# RL7005_IP_SVD register map
Vendor: Realtek
Registers are 32-bit, read-write, reset 0x0 unless marked. A register's access mark holds for its fields unless they carry their own. Offsets are from the block's base; [hi:lo] are bit positions; {n}, {i} and the like mark numbered series.

## TIMER0_REG
Base 0x40819000
Same registers: TIMER1_REG 0x40819200, TIMER2_REG 0x40819400, TIMER3_REG 0x40819600, TIMER4_REG 0x41000000, TIMER5_REG 0x41000200, TIMER6_REG 0x41000400, TIMER7_REG 0x41000600, TIMER8_REG 0x41000800, UPS_REG 0x41000A00
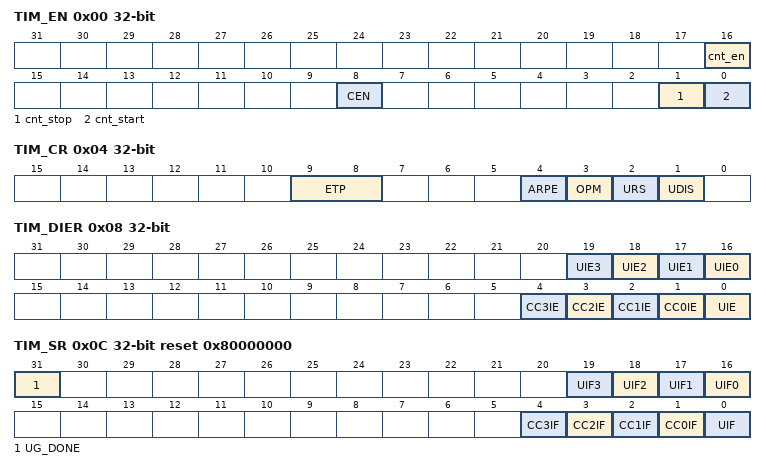
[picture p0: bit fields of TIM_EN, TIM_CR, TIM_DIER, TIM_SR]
0x00 TIM_EN access per field — TIM enable register
  [16] cnt_en ro — counter working status * 0: counter is stoppped * 1: counter is working
  [8] CEN ro — counter run status * 0: counter is disabled * 1: counter is enabled
  [1] cnt_stop wo — disable the counter. Poll CNT_RUN to see the counter status. If CNT_RUN is 0, it means that the counter has been disabled internally.
  [0] cnt_start wo — enable the counter. Poll CNT_RUN to see the counter status. If CNT_RUN is 1, it means that the counter has been enabled internally.
0x04 TIM_CR — TIM control register
  [9:8] ETP — external trigger polarity(TRGI) * 0: positive edge is active * 1: negative edge is active * 2 or 3: both edge is active Note: these bits are only valid in one-pulse mode.
  [4] ARPE — enable auto-reload preloading * 0: TIM_ARR register is not buffered * 1: TIM_ARR register is buffered
  [3] OPM — one-pulse mode * 0: counter is not stopped at UEV * 1: counter stops counting at next UEV
  [2] URS — update request source * 0: counter overflow and setting the UG bit * 1: counter overflow
  [1] UDIS — disable UEV. Shadow registers keep their values. Otherwise, buffered registers are then loaded with their preload values when UEV happen.
0x08 TIM_DIER — TIM interupt enable register
  [n+16] UIE{n} (n=0..3) — enable channel {n} update interrupt
  [n+1] CC{n}IE (n=0..3) — enable Capture/Compare {n} interrupt
  [0] UIE — enable counter update interrupt
0x0C TIM_SR ro reset 0x80000000 — TIM status register
  [31] UG_DONE — UG operation status This bit is cleared by hardware when the UG bit in the TIMx_EGR register is set. When the UG operation is done, hardware set this bit to '1'. So, software can poll this bit to see the UG operation status.
  [19] UIF3 — refer to UIF0 description
  [18] UIF2 — refer to UIF0 description
  [17] UIF1 — refer to UIF0 description
  [16] UIF0 — update interrupt flag of channel0 This flag is set by hardware when the UIE0 bit in the TIMx_EGR register is set, and update interrupt of channel0 happens.
  [4] CC3IF — refer to CC0IF description
  [3] CC2IF — refer to CC0IF description
  [2] CC1IF — refer to CC0IF description
  [1] CC0IF — Capture/Compare 0 interrupt flag channel CC0 configured as output: This flag is set by hardware when the counter TIM_CNT value matches the value of TIM_CCR0 register. It is cleared by software. Channel CC0 configured as input: This flag is set by hardware and the counter value has been captured in CCR0 field of TIM_CCR0 register when an active edge has been detected. It is cleared by software.
  [0] UIF — update interrupt flag
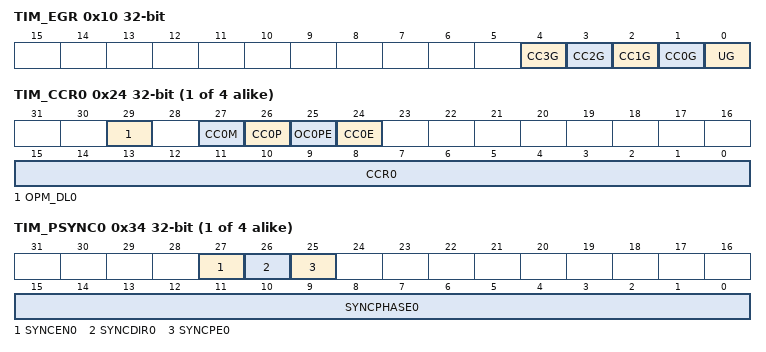
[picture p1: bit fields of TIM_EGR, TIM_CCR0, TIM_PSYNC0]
0x10 TIM_EGR wo — TIM event generation register
  [4] CC3G — refer to CC0G description
  [3] CC2G — refer to CC0G description
  [2] CC1G — refer to CC0G description
  [1] CC0G — Capture/Compare 0 generation This bit is set by software and is automatically cleared by hardware. channel CC0 configured as output: The CC0IF flag is set, the corresponding interrupt or request is sent if enabled. Channel CC0 configured as input: The current value of counter is capture in CCR0 field of TIM_CCR0 register. The CC0IF flag is set, the corresponding interrupt or request is sent if enabled.
  [0] UG — update generation. Re-initialize the counter and generate an update of registers. Note that the prescaler counter is cleared too.(anyway the prescaler ratio is not affected)
0x14 TIM_CNT ro — TIM counter
  [15:0] CNT — counter value
0x18 TIM_PSC — TIM prescaler register
  [15:0] PSC — prescaler value. PSC contains the value to be loaded in the actual prescaler register at each UEV(including when the counter is cleared through UG bit of TIM_EGR register).
0x1C TIM_ARR reset 0xFFFF — TIM auto-reload register
  [15:0] ARR — the value to be loaded in the actual auto-reload register. It can be preloaded by setting ARPE bit in TIM_CR.
{0x24+4i} TIM_CCR{i} (i=0..3) — TIM Capture/Compare register {i}
  [29] OPM_DL{i} — One Pulse Mode default level 0: default level is 0 1: default level is 1 this bit takes effect only in PWM output mode's One-Pulse-Mode
  [27] CC{i}M — CC{i} working mode * 0: PWM mode * 1: Input capture mode
  [26] CC{i}P — CC{i} channel configured as output: * 0: OC{i} active high * 1: OC{i} ative low CC{i} channel configured as input: * 0: positive edge of TRGI is active for capture * 1: negative edge of TRGI is active for capture
  [25] OC{i}PE — enable output capture {i} preload * 0: disable preload register on CCR{i}. CCR{i} can be written at any time, the new value is taken into account immediately. * 1: enable preload register on CCR{i}. Read/Write operations access the preload register. CCR{i} preload value is loaded in the active register at each UEV.
  [24] CC{i}E — enable CC{i}
  [15:0] CCR{i} — Capture/Compare {i} value CC{i} channel configured as output: CCR{i} is the value to be loaded in the actual capture/compare {i} register(preload value). It is loaded permanently if the preload feature is not selected in the OC{i}PE bit.Else the preload value is copied in the active capture/compare {i} register when an UEV occurs.The active capture/compare {i} register contains the value to be compared to the counter TIM_CNT and signalled on OC{i} output. CC{i} channel configured as pulse mode 1: CCR{i} is the counter value transferred by the last input capture event(TRGI)
{0x34+4i} TIM_PSYNC{i} (i=0..3) — TIM Phase Synchronization register {i}
  [27] SYNCEN{i} — enable phase sync function in channel {i}. Phase sync takes effect only in output PWM mode.
  [26] SYNCDIR{i} — phase sync direction to the reference counter: 0:delay to the reference counter 1:ahead to the reference counter
  [25] SYNCPE{i} — enable sync phase parameter preload * 0: disable preload register on PSYNC{i}. PSYNC{i} can be written at any time, the new value is taken into account immediately. * 1: enable preload register on PSYNC{i}. Read/Write operations access the preload register. PSYNC{i} preload value is loaded in the active register at each UEV.
  [15:0] SYNCPHASE{i} — the deviation value of channel{i} to the reference counter
{0x44+4i} TIM_PHASECNT{i} ro (i=0..3) — TIM phase counter register {i}
  [15:0] CNT{i} — phase counter value of channel{i}
0x54 REG_TIM_PWM_DUMMY reset 0xFFFF — Timer PWM Dummy Register
